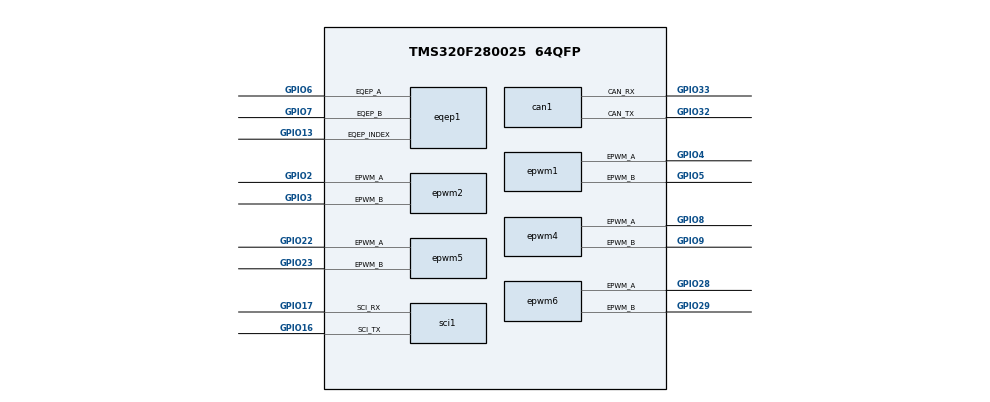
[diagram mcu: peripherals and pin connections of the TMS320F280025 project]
/**
 * These arguments were used when this file was generated. They will be automatically applied on subsequent loads
 * via the GUI or CLI. Run CLI with '--help' for additional information on how to override these arguments.
 * @cliArgs --device "F28002x" --part "F28002x_64QFP" --package "64QFP" --context "system" --product "gmp_pro@1.00.00.05" --product "C2000WARE@5.03.00.00"
 * @v2CliArgs --device "TMS320F280025" --package "64QFP" --context "system" --product "gmp_pro@1.00.00.05" --product "C2000WARE@5.03.00.00"
 * @versions {"tool":"1.21.0+3721"}
 */

/**
 * Import the modules used in this configuration.
 */
const adc            = scripting.addModule("/driverlib/adc.js", {}, false);
const adc1           = adc.addInstance();
const adc2           = adc.addInstance();
const analog         = scripting.addModule("/driverlib/analog.js", {}, false);
const analog1        = analog.addInstance();
const can            = scripting.addModule("/driverlib/can.js", {}, false);
const can1           = can.addInstance();
const cputimer       = scripting.addModule("/driverlib/cputimer.js", {}, false);
const cputimer1      = cputimer.addInstance();
const device_support = scripting.addModule("/driverlib/device_support.js");
const epwm           = scripting.addModule("/driverlib/epwm.js", {}, false);
const epwm1          = epwm.addInstance();
const epwm2          = epwm.addInstance();
const epwm3          = epwm.addInstance();
const epwm4          = epwm.addInstance();
const epwm5          = epwm.addInstance();
const epwm6          = epwm.addInstance();
const eqep           = scripting.addModule("/driverlib/eqep.js", {}, false);
const eqep1          = eqep.addInstance();
const gpio           = scripting.addModule("/driverlib/gpio.js", {}, false);
const gpio1          = gpio.addInstance();
const gpio2          = gpio.addInstance();
const gpio3          = gpio.addInstance();
const gpio4          = gpio.addInstance();
const gpio5          = gpio.addInstance();
const gpio6          = gpio.addInstance();
const i2c            = scripting.addModule("/driverlib/i2c.js", {}, false);
const i2c1           = i2c.addInstance();
const other          = scripting.addModule("/driverlib/other.js", {}, false);
const other1         = other.addInstance();
const sci            = scripting.addModule("/driverlib/sci.js", {}, false);
const sci1           = sci.addInstance();

/**
 * Write custom configuration values to the imported modules.
 */
adc1.$name             = "CLLLC_ADCA";
adc1.adcClockPrescaler = "ADC_CLK_DIV_2_0";
adc1.enabledSOCs       = ["ADC_SOC_NUMBER0","ADC_SOC_NUMBER1","ADC_SOC_NUMBER2"];
adc1.soc0SampleWindow  = 8;
adc1.soc0Name = "PRIMARY_CURRENT"; adc1.soc0IndependentNameMode = true;
adc1.soc0Channel = "ADC_CH_ADCIN6"; adc1.soc0Trigger = "ADC_TRIGGER_EPWM1_SOCA";
adc1.soc1Name = "SECONDARY_CURRENT"; adc1.soc1IndependentNameMode = true;
adc1.soc1Channel = "ADC_CH_ADCIN2"; adc1.soc1SampleWindow = 8; adc1.soc1Trigger = "ADC_TRIGGER_EPWM1_SOCA";
adc1.soc2Name = "SECONDARY_VOLTAGE"; adc1.soc2IndependentNameMode = true;
adc1.soc2Channel = "ADC_CH_ADCIN3"; adc1.soc2SampleWindow = 8; adc1.soc2Trigger = "ADC_TRIGGER_EPWM1_SOCA";
adc1.enabledInts = ["ADC_INT_NUMBER1"];
adc1.enableInterrupt1 = true;
adc1.registerInterrupts = ["1"];
adc1.adcInt1.interruptHandler = "MainISR";
adc1.adcInt1.enableInterrupt = true;

adc2.$name             = "CLLLC_ADCC";
adc2.adcBase           = "ADCC_BASE";
adc2.adcClockPrescaler = "ADC_CLK_DIV_2_0";
adc2.enabledSOCs       = ["ADC_SOC_NUMBER0"];
adc2.soc0Name = "PRIMARY_VOLTAGE"; adc2.soc0IndependentNameMode = true;
adc2.soc0Channel = "ADC_CH_ADCIN6"; adc2.soc0SampleWindow = 8; adc2.soc0Trigger = "ADC_TRIGGER_EPWM1_SOCA";

analog1.$name            = "myANALOGPinMux0";
adc1.analog              = analog1;
adc2.analog              = analog1;
analog1.useCase          = "CUSTOM";
analog1.useInterfacePins = ["A0/C15","A1","A10/C10","A11/C0","A12/C1","A14/C4","A15/C7","A2/C9","A3/C5/VDAC","A4/C14","A5/C2","A6","A7/C3","A8/C11","A9/C8","C6"];

can1.$name                   = "COMM_CAN";
can1.enableAutoBusOn         = true;
can1.AutoBusOnTimer          = 128;
can1.enableInterrupt         = true;
can1.registerInterrupts      = true;
can1.interruptFlags          = ["CAN_INT_IE0"];
can1.interruptLine           = ["CAN_GLOBAL_INT_CANINT0"];
/* F280025 CANA is only muxable to GPIO33/32 in this package.  The schematic
 * labels GPIO30/31 at the transceiver, which cannot be selected as CANA by
 * the device pinmux and must be corrected in the next PCB revision. */
can1.can.can_rxPin.$assign   = "GPIO33";
can1.can.can_txPin.$assign   = "GPIO32";
can1.can0Int.enableInterrupt = true;

epwm1.$name                  = "CLLLC_EPWM3";
epwm1.epwm.$assign           = "EPWM3";
epwm1.epwm.epwm_aPin.$assign = "GPIO4";
epwm1.epwm.epwm_bPin.$assign = "GPIO5";

epwm2.$name                  = "CLLLC_EPWM2";
epwm2.epwm.$assign           = "EPWM2";
epwm2.epwm.epwm_aPin.$assign = "GPIO2";
epwm2.epwm.epwm_bPin.$assign = "GPIO3";

epwm3.$name        = "CLLLC_EPWM1";
epwm3.epwm.$assign = "EPWM1";

epwm4.$name                  = "myEPWM3";
epwm4.epwm.epwm_aPin.$assign = "GPIO8";
epwm4.epwm.epwm_bPin.$assign = "GPIO9";

epwm5.$name                  = "CLLLC_EPWM4";
epwm5.epwm.epwm_aPin.$assign = "GPIO22";
epwm5.epwm.epwm_bPin.$assign = "GPIO23";

epwm6.$name                  = "myEPWM5";
epwm6.epwm.epwm_aPin.$assign = "GPIO28";
epwm6.epwm.epwm_bPin.$assign = "GPIO29";

eqep1.$name                      = "myEQEP0";
eqep1.useCase                    = "NO STROBE";
eqep1.eqep.$assign               = "EQEP1";
eqep1.eqep.eqep_aPin.$assign     = "GPIO6";
eqep1.eqep.eqep_bPin.$assign     = "GPIO7";
eqep1.eqep.eqep_indexPin.$assign = "GPIO13";

gpio1.$name = "myGPIO0";

gpio2.$name = "myGPIO1";

gpio3.$name = "myGPIO2";

gpio4.$name = "myGPIO3";

gpio5.$name = "myGPIO4";

gpio6.$name = "myGPIO5";

i2c1.$name = "myI2C0";

other1.$name            = "myOTHER0";
other1.useCase          = "CUSTOM";
other1.useInterfacePins = ["TCK","TDI","TDO","TMS","X1"];

sci1.$name                      = "UART_USB";
sci1.enabledFIFOInterrupts      = ["SCI_INT_RXFF"];
sci1.selectRegisteredInterrupts = ["registerRxInt"];
sci1.sci.$assign                = "SCIA";
sci1.sci.sci_rxPin.$assign      = "GPIO17";
sci1.sci.sci_txPin.$assign      = "GPIO16";
sci1.rxQual.$name               = "myGPIOQUAL0";
sci1.txQual.$name               = "myGPIOQUAL1";

cputimer1.$name = "CLLLC_TICK_TIMER";
cputimer1.timerPeriod = 1000;

/**
 * Pinmux solution for unlocked pins/peripherals. This ensures that minor changes to the automatic solver in a future
 * version of the tool will not impact the pinmux you originally saw.  These lines can be completely deleted in order to
 * re-solve from scratch.
 */
analog1.analog.$suggestSolution                  = "ANALOG";
analog1.analog["a0/c15Pin"].$suggestSolution     = "A0/C15";
analog1.analog.a1Pin.$suggestSolution            = "A1";
analog1.analog["a10/c10Pin"].$suggestSolution    = "A10/C10";
analog1.analog["a11/c0Pin"].$suggestSolution     = "A11/C0";
analog1.analog["a12/c1Pin"].$suggestSolution     = "A12/C1";
analog1.analog["a14/c4Pin"].$suggestSolution     = "A14/C4";
analog1.analog["a15/c7Pin"].$suggestSolution     = "A15/C7";
analog1.analog["a2/c9Pin"].$suggestSolution      = "A2/C9";
analog1.analog["a3/c5/vdacPin"].$suggestSolution = "A3/C5/VDAC";
analog1.analog["a4/c14Pin"].$suggestSolution     = "A4/C14";
analog1.analog["a5/c2Pin"].$suggestSolution      = "A5/C2";
analog1.analog.a6Pin.$suggestSolution            = "A6";
analog1.analog["a7/c3Pin"].$suggestSolution      = "A7/C3";
analog1.analog["a8/c11Pin"].$suggestSolution     = "A8/C11";
analog1.analog["a9/c8Pin"].$suggestSolution      = "A9/C8";
analog1.analog.c6Pin.$suggestSolution            = "C6";
can1.can.$suggestSolution                        = "CANA";
epwm3.epwm.epwm_aPin.$suggestSolution            = "GPIO0";
epwm3.epwm.epwm_bPin.$suggestSolution            = "GPIO1";
epwm4.epwm.$suggestSolution                      = "EPWM5";
epwm5.epwm.$suggestSolution                      = "EPWM4";
epwm6.epwm.$suggestSolution                      = "EPWM7";
gpio1.gpioPin.$suggestSolution                   = "GPIO12";
gpio2.gpioPin.$suggestSolution                   = "GPIO11";
gpio3.gpioPin.$suggestSolution                   = "GPIO24";
gpio4.gpioPin.$suggestSolution                   = "GPIO39";
gpio5.gpioPin.$suggestSolution                   = "GPIO40";
gpio6.gpioPin.$suggestSolution                   = "GPIO41";
i2c1.i2c.$suggestSolution                        = "I2CA";
i2c1.i2c.i2c_sdaPin.$suggestSolution             = "GPIO10";
i2c1.i2c.i2c_sclPin.$suggestSolution             = "GPIO18_X2";
other1.other.$suggestSolution                    = "OTHER";
other1.other.tdoPin.$suggestSolution             = "GPIO37/TDO";
other1.other.tdiPin.$suggestSolution             = "GPIO35/TDI";
other1.other.x1Pin.$suggestSolution              = "GPIO19_X1";
